AUTOSAR XML (schema 4-3-0)
package /Impl_SWC_FDC_ARPkg
  swc implementation Impl_SWC_FDC_type: programming-language=C, sw-version=1.0.0, vendor-id=0, behavior=SWC_FDC_type_IB
    code-descriptors:
      code SRC: artifact-descriptors=autosar-engineering-object={short-label=EngObject, category=SWSRC}
    resource consumption ResourceConsumption
      memory section MEM_SWC_FDC_CAL: size=0, sw-addrmethod=CAL, symbol=CAL
      memory section MEM_SWC_FDC_CODE: size=0, sw-addrmethod=CODE, symbol=CODE
package /SWC_FDC_ARPkg
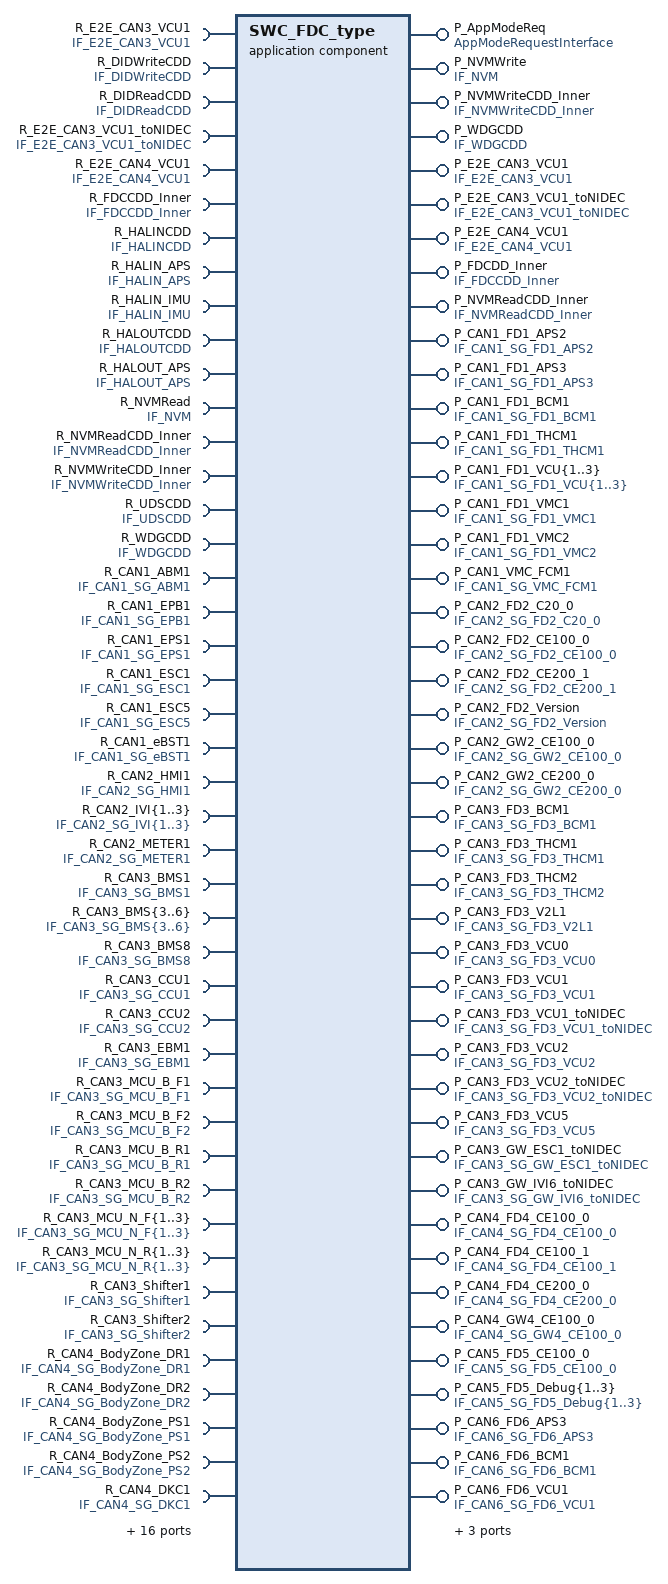
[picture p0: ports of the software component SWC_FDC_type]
  application sw component type SWC_FDC_type
    51 x provide port:
      P_AppModeReq: provided-interface=AppModeRequestInterface
      P_NVMWrite: nv-provide-com-spec{ram-block-init-value=ValueSpecification_:256 x 0, rom-block-init-value=ValueSpecification_:256 x 0, variable=NV_FVTDataArray}, provided-interface=IF_NVM
      P_NVMWriteCDD_Inner: provided-interface=IF_NVMWriteCDD_Inner
      P_WDGCDD: provided-interface=IF_WDGCDD
      P_E2E_CAN3_VCU1: provided-interface=IF_E2E_CAN3_VCU1
      P_E2E_CAN3_VCU1_toNIDEC: provided-interface=IF_E2E_CAN3_VCU1_toNIDEC
      P_E2E_CAN4_VCU1: provided-interface=IF_E2E_CAN4_VCU1
      P_FDCDD_Inner: provided-interface=IF_FDCCDD_Inner
      P_NVMReadCDD_Inner: provided-interface=IF_NVMReadCDD_Inner
      P_CAN1_FD1_APS2: provided-interface=IF_CAN1_SG_FD1_APS2
      P_CAN1_FD1_APS3: provided-interface=IF_CAN1_SG_FD1_APS3
      P_CAN1_FD1_BCM1: provided-interface=IF_CAN1_SG_FD1_BCM1
      P_CAN1_FD1_THCM1: provided-interface=IF_CAN1_SG_FD1_THCM1
      P_CAN1_FD1_VCU{1..3}: provided-interface=IF_CAN1_SG_FD1_VCU{1..3}
      P_CAN1_FD1_VMC1: provided-interface=IF_CAN1_SG_FD1_VMC1
      P_CAN1_FD1_VMC2: provided-interface=IF_CAN1_SG_FD1_VMC2
      P_CAN1_VMC_FCM1: provided-interface=IF_CAN1_SG_VMC_FCM1
      P_CAN2_FD2_C20_0: provided-interface=IF_CAN2_SG_FD2_C20_0
      P_CAN2_FD2_CE100_0: provided-interface=IF_CAN2_SG_FD2_CE100_0
      P_CAN2_FD2_CE200_1: provided-interface=IF_CAN2_SG_FD2_CE200_1
      P_CAN2_FD2_Version: provided-interface=IF_CAN2_SG_FD2_Version
      P_CAN2_GW2_CE100_0: provided-interface=IF_CAN2_SG_GW2_CE100_0
      P_CAN2_GW2_CE200_0: provided-interface=IF_CAN2_SG_GW2_CE200_0
      P_CAN3_FD3_BCM1: provided-interface=IF_CAN3_SG_FD3_BCM1
      P_CAN3_FD3_THCM1: provided-interface=IF_CAN3_SG_FD3_THCM1
      P_CAN3_FD3_THCM2: provided-interface=IF_CAN3_SG_FD3_THCM2
      P_CAN3_FD3_V2L1: provided-interface=IF_CAN3_SG_FD3_V2L1
      P_CAN3_FD3_VCU0: provided-interface=IF_CAN3_SG_FD3_VCU0
      P_CAN3_FD3_VCU1: provided-interface=IF_CAN3_SG_FD3_VCU1
      P_CAN3_FD3_VCU1_toNIDEC: provided-interface=IF_CAN3_SG_FD3_VCU1_toNIDEC
      P_CAN3_FD3_VCU2: provided-interface=IF_CAN3_SG_FD3_VCU2
      P_CAN3_FD3_VCU2_toNIDEC: provided-interface=IF_CAN3_SG_FD3_VCU2_toNIDEC
      P_CAN3_FD3_VCU5: provided-interface=IF_CAN3_SG_FD3_VCU5
      P_CAN3_GW_ESC1_toNIDEC: provided-interface=IF_CAN3_SG_GW_ESC1_toNIDEC
      P_CAN3_GW_IVI6_toNIDEC: provided-interface=IF_CAN3_SG_GW_IVI6_toNIDEC
      P_CAN4_FD4_CE100_0: provided-interface=IF_CAN4_SG_FD4_CE100_0
      P_CAN4_FD4_CE100_1: provided-interface=IF_CAN4_SG_FD4_CE100_1
      P_CAN4_FD4_CE200_0: provided-interface=IF_CAN4_SG_FD4_CE200_0
      P_CAN4_GW4_CE100_0: provided-interface=IF_CAN4_SG_GW4_CE100_0
      P_CAN5_FD5_CE100_0: provided-interface=IF_CAN5_SG_FD5_CE100_0
      P_CAN5_FD5_Debug{1..3}: provided-interface=IF_CAN5_SG_FD5_Debug{1..3}
      P_CAN6_FD6_APS3: provided-interface=IF_CAN6_SG_FD6_APS3
      P_CAN6_FD6_BCM1: provided-interface=IF_CAN6_SG_FD6_BCM1
      P_CAN6_FD6_VCU1: provided-interface=IF_CAN6_SG_FD6_VCU1
      P_CAN6_FD6_VCU2: provided-interface=IF_CAN6_SG_FD6_VCU2
      P_CAN6_FD6_VMC1: provided-interface=IF_CAN6_SG_FD6_VMC1
      P_CAN6_GW6_CE100_0: provided-interface=IF_CAN6_SG_GW6_CE100_0
    74 x require port:
      R_E2E_CAN3_VCU1: required-interface=IF_E2E_CAN3_VCU1
      R_DIDWriteCDD: required-interface=IF_DIDWriteCDD
      R_DIDReadCDD: required-interface=IF_DIDReadCDD
      R_E2E_CAN3_VCU1_toNIDEC: required-interface=IF_E2E_CAN3_VCU1_toNIDEC
      R_E2E_CAN4_VCU1: required-interface=IF_E2E_CAN4_VCU1
      R_FDCCDD_Inner: required-interface=IF_FDCCDD_Inner
      R_HALINCDD: required-interface=IF_HALINCDD
      R_HALIN_APS: required-interface=IF_HALIN_APS
      R_HALIN_IMU: required-interface=IF_HALIN_IMU
      R_HALOUTCDD: required-interface=IF_HALOUTCDD
      R_HALOUT_APS: required-interface=IF_HALOUT_APS
      R_NVMRead: nv-require-com-spec{init-value=256 x 0, variable=NV_FVTDataArray}, required-interface=IF_NVM
      R_NVMReadCDD_Inner: required-interface=IF_NVMReadCDD_Inner
      R_NVMWriteCDD_Inner: required-interface=IF_NVMWriteCDD_Inner
      R_UDSCDD: required-interface=IF_UDSCDD
      R_WDGCDD: required-interface=IF_WDGCDD
      R_CAN1_ABM1: required-interface=IF_CAN1_SG_ABM1
      R_CAN1_EPB1: required-interface=IF_CAN1_SG_EPB1
      R_CAN1_EPS1: required-interface=IF_CAN1_SG_EPS1
      R_CAN1_ESC1: required-interface=IF_CAN1_SG_ESC1
      R_CAN1_ESC5: required-interface=IF_CAN1_SG_ESC5
      R_CAN1_eBST1: required-interface=IF_CAN1_SG_eBST1
      R_CAN2_HMI1: required-interface=IF_CAN2_SG_HMI1
      R_CAN2_IVI{1..3}: required-interface=IF_CAN2_SG_IVI{1..3}
      R_CAN2_METER1: required-interface=IF_CAN2_SG_METER1
      R_CAN3_BMS1: required-interface=IF_CAN3_SG_BMS1
      R_CAN3_BMS{3..6}: required-interface=IF_CAN3_SG_BMS{3..6}
      R_CAN3_BMS8: required-interface=IF_CAN3_SG_BMS8
      R_CAN3_CCU1: required-interface=IF_CAN3_SG_CCU1
      R_CAN3_CCU2: required-interface=IF_CAN3_SG_CCU2
      R_CAN3_EBM1: required-interface=IF_CAN3_SG_EBM1
      R_CAN3_MCU_B_F1: required-interface=IF_CAN3_SG_MCU_B_F1
      R_CAN3_MCU_B_F2: required-interface=IF_CAN3_SG_MCU_B_F2
      R_CAN3_MCU_B_R1: required-interface=IF_CAN3_SG_MCU_B_R1
      R_CAN3_MCU_B_R2: required-interface=IF_CAN3_SG_MCU_B_R2
      R_CAN3_MCU_N_F{1..3}: required-interface=IF_CAN3_SG_MCU_N_F{1..3}
      R_CAN3_MCU_N_R{1..3}: required-interface=IF_CAN3_SG_MCU_N_R{1..3}
      R_CAN3_Shifter1: required-interface=IF_CAN3_SG_Shifter1
      R_CAN3_Shifter2: required-interface=IF_CAN3_SG_Shifter2
      R_CAN4_BodyZone_DR1: required-interface=IF_CAN4_SG_BodyZone_DR1
      R_CAN4_BodyZone_DR2: required-interface=IF_CAN4_SG_BodyZone_DR2
      R_CAN4_BodyZone_PS1: required-interface=IF_CAN4_SG_BodyZone_PS1
      R_CAN4_BodyZone_PS2: required-interface=IF_CAN4_SG_BodyZone_PS2
      R_CAN4_DKC1: required-interface=IF_CAN4_SG_DKC1
      R_CAN4_DKC2: required-interface=IF_CAN4_SG_DKC2
      R_CAN4_PTG1: required-interface=IF_CAN4_SG_PTG1
      R_CAN4_ZONE_DR1: required-interface=IF_CAN4_SG_ZONE_DR1
      R_CAN4_ZONE_DR_VCU: required-interface=IF_CAN4_SG_ZONE_DR_VCU
      R_CAN4_ZONE_FR1: required-interface=IF_CAN4_SG_ZONE_FR1
      R_CAN4_ZONE_FR_VCU: required-interface=IF_CAN4_SG_ZONE_FR_VCU
      R_CAN4_zGW_APTC1: required-interface=IF_CAN4_SG_zGW_APTC1
      R_CAN4_zGW_CANFr1: required-interface=IF_CAN4_SG_zGW_CANFr1
      R_CAN4_zGW_LINDr1: required-interface=IF_CAN4_SG_zGW_LINDr1
      R_CAN4_zGW_LINDr2: required-interface=IF_CAN4_SG_zGW_LINDr2
      R_CAN4_zGW_LINFr1: required-interface=IF_CAN4_SG_zGW_LINFr1
      R_CAN4_zGW_LINFr2: required-interface=IF_CAN4_SG_zGW_LINFr2
      R_CAN4_zGW_SEAT1: required-interface=IF_CAN4_SG_zGW_SEAT1
      R_CAN5_TBOX{1..3}: required-interface=IF_CAN5_SG_TBOX{1..3}
      R_CAN6_FCM{1..4}: required-interface=IF_CAN6_SG_FCM{1..4}
      R_CAN6_SRR1: required-interface=IF_CAN6_SG_SRR1
    behavior SWC_FDC_type_IB: data-type-mapping=AppModeTypeMap, handle-termination-and-restart=NO-SUPPORT
      10 x timing event:
        TE_100ms: start-on-event=run_SWC_FDC_Tx_100ms, period=0.1
        TE_1000ms: start-on-event=run_SWC_FDC_Tx_1000ms, period=1
        TE_20ms: start-on-event=run_SWC_FDC_Tx_20ms, period=0.02
        TE_500ms: start-on-event=run_SWC_FDC_Tx_500ms, period=0.5
        TE_5000ms: start-on-event=run_SWC_FDC_Tx_5000ms, period=5
        TE_10ms: start-on-event=run_SWC_FDC_Tx_10ms, period=0.01
        TE_5ms: start-on-event=run_SWC_FDC_RxTx_5ms, period=0.005
        TE_CDD_10ms: start-on-event=run_SWC_FDC_CDD_10ms, period=0.01
        TE_PAS_1ms: start-on-event=run_SWC_FDC_PAS_1ms, period=0.001
        TE_UDS_10ms: start-on-event=run_SWC_FDC_UDS_10ms, period=0.01
      9 x operation invoked event:
        oie_P_E2E_CAN3_VCU1_CSOP_Write_CAN3_VCU1: start-on-event=run_SWC_FDC_E2E_Write_CAN3VCU1, operation=P_E2E_CAN3_VCU1.CSOP_Write_CAN3_VCU1
        oie_P_E2E_CAN3_VCU1_CSOP_Write_CAN3_VCU1_toNIDEC: start-on-event=run_SWC_FDC_E2E_Write_CAN3VCU1_toNIDEC, operation=P_E2E_CAN3_VCU1_toNIDEC.CSOP_Write_CAN3_VCU1_toNIDEC
        oie_P_E2E_CAN4_VCU1_CSOP_Write_CAN4_VCU1: start-on-event=run_SWC_FDC_E2E_Write_CAN4VCU1, operation=P_E2E_CAN4_VCU1.CSOP_Write_CAN4_VCU1
        oie_P_FDCDD_Inner_CSOP_FDC_AppCallSleep: start-on-event=run_SWC_FDC_AppCallSleep, operation=P_FDCDD_Inner.CSOP_FDC_AppCallSleep
        oie_P_NVMReadCDD_Inner_NVM_ReadOperation: start-on-event=run_SWC_FDC_NvmRead, operation=P_NVMReadCDD_Inner.NVM_ReadOperation
        oie_P_NVMWriteCDD_Inner_NVM_WriteOperation: start-on-event=run_SWC_FDC_NvmWrite, operation=P_NVMWriteCDD_Inner.NVM_WriteOperation
        oie_P_WDGCDD_CSOP_Call_WDG_AppEnd: start-on-event=run_SWC_FDC_AppCallWDG_End, operation=P_WDGCDD.CSOP_Call_WDG_AppEnd
        oie_P_WDGCDD_CSOP_Call_WDG_AppStart: start-on-event=run_SWC_FDC_AppCallWDG_StartUp, operation=P_WDGCDD.CSOP_Call_WDG_AppStart
        oie_P_WDGCDD_CSOP_Call_Watchdog: start-on-event=run_SWC_FDC_AppCallWDG, operation=P_WDGCDD.CSOP_Call_Watchdog
      explicit-inter-runnable-variables:
        51 x data:
          IRV_ms10_CAN1_SG_FD1_APS3: type=DT_CAN1_SG_FD1_APS3
          IRV_ms10_CAN1_SG_FD1_VCU2: type=DT_CAN1_SG_FD1_VCU2
          IRV_ms10_CAN1_SG_FD1_VCU3: type=DT_CAN1_SG_FD1_VCU3
          IRV_ms10_CAN1_SG_VMC_FCM1: type=DT_CAN1_SG_VMC_FCM1
          IRV_ms10_CAN3_SG_FD3_VCU0: type=DT_CAN3_SG_FD3_VCU0
          IRV_ms10_CAN3_SG_FD3_VCU2: type=DT_CAN3_SG_FD3_VCU2
          IRV_ms10_CAN3_SG_FD3_VCU2_toNIDEC: type=DT_CAN3_SG_FD3_VCU2_toNIDEC
          IRV_ms10_CAN3_SG_FD3_VCU5: type=DT_CAN3_SG_FD3_VCU5
          IRV_ms10_CAN3_SG_GW_ESC1_toNIDEC: type=DT_CAN3_SG_GW_ESC1_toNIDEC
          IRV_ms10_CAN5_SG_FD5_Debug3: type=DT_CAN5_SG_FD5_Debug3
          IRV_ms10_CAN6_SG_FD6_APS3: type=DT_CAN6_SG_FD6_APS3
          IRV_ms10_CAN6_SG_FD6_VCU2: type=DT_CAN6_SG_FD6_VCU2
          IRV_ms100_CAN1_SG_FD1_THCM1: type=DT_CAN1_SG_FD1_THCM1
          IRV_ms100_CAN3_SG_FD3_THCM1: type=DT_CAN3_SG_FD3_THCM1
          IRV_ms1000_CAN3_SG_GW_IVI6_toNIDEC: type=DT_CAN3_SG_GW_IVI6_toNIDEC
          IRV_ms20_CAN1_SG_FD1_APS2: type=DT_CAN1_SG_FD1_APS2
          IRV_ms20_CAN2_SG_FD2_C20_0: type=DT_CAN2_SG_FD2_C20_0
          IRV_ms500_CAN1_SG_FD1_VMC2: type=DT_CAN1_SG_FD1_VMC2
          IRV_ms5000_CAN2_SG_FD2_Version: type=DT_CAN2_SG_FD2_Version
          IRV_E2E_CAN3_SG_FD3_VCU1: type=DT_CAN3_SG_FD3_VCU1
          IRV_E2E_CAN3_SG_FD3_VCU1_toNIDEC: type=DT_CAN3_SG_FD3_VCU1_toNIDEC
          IRV_E2E_CAN4_SG_FD4_CE100_0: type=DT_CAN4_SG_FD4_CE100_0
          IRV_f32_ApsOutVehSpdSig: type=float32
          IRV_u16Array4_ApsInDist: type=u16_APSArray4_type
          IRV_u8Array12_ApsInUssSta: type=u8_USSArray12_type
          IRV_u8Array256_NvmReadArray: type=u8_FVTNVMArray256_type
          IRV_u8Array256_NvmWriteArray: type=u8_FVTNVMArray256_type
          IRV_u8Array8_ApsInLevel: type=u8_APSLevelArray8_type
          IRV_u8Array8_PasInDist: type=u8_PASArray8_type
          IRV_u8Array9_TPMSData: type=u8_TPMSDataArray9_type
          IRV_u8_ApsInPASChime: type=uint8
          IRV_u8_ApsInSensorLayout: type=uint8
          IRV_u8_ApsInSysFailSta: type=uint8
          IRV_u8_ApsInSysMode: type=uint8
          IRV_u8_ApsOutGearPosnSig: type=uint8
          IRV_u8_ApsOutSendChrgPlugSta: type=uint8
          IRV_u8_ApsOutSetFrSensorOnCmd: type=uint8
          IRV_u8_ApsOutSetFrSensorSwTOCmd: type=uint8
          IRV_u8_ApsOutSetVehSpdTOCmd: type=uint8
          IRV_u8_CTDSW: type=uint8
          IRV_u8_CrashSignal: type=uint8
          IRV_u8_DrDoorSW: type=uint8
          IRV_u8_HazardSW: type=uint8
          IRV_u8_HoodSW: type=uint8
          IRV_u8_PsDoorSW: type=uint8
          IRV_u8_RLDoorSW: type=uint8
          IRV_u8_RRDoorSW: type=uint8
          IRV_u8_SeatSW: type=uint8
          IRV_u8_TPMSDataInSta: type=boolean
          IRV_u8_TailgateSW: type=uint8
          IRV_u8_TrunkHanSW: type=uint8
      port-api-options:
        enable-take-address=false, indirect-api=false, port=P_FDCDD_Inner
        enable-take-address=false, indirect-api=false, port=P_NVMReadCDD_Inner
        enable-take-address=false, indirect-api=false, port=P_NVMWriteCDD_Inner
        enable-take-address=false, indirect-api=false, port=P_E2E_CAN3_VCU1
        enable-take-address=false, indirect-api=false, port=P_E2E_CAN3_VCU1_toNIDEC
        enable-take-address=false, indirect-api=false, port=P_E2E_CAN4_VCU1
        enable-take-address=false, indirect-api=false, port=P_WDGCDD
      19 x runnable:
        run_SWC_FDC_Tx_100ms
          data-send-points:
            access dsp_CAN1_SG_FD1_THCM1: accessed-variable=P_CAN1_FD1_THCM1.CAN1_SG_FD1_THCM1
            access dsp_CAN3_SG_FD3_THCM1: accessed-variable=P_CAN3_FD3_THCM1.CAN3_SG_FD3_THCM1
          read-local-variables:
            access IRV_ms100_CAN1_SG_FD1_THCM1: accessed-variable=IRV_ms100_CAN1_SG_FD1_THCM1
            access IRV_ms100_CAN3_SG_FD3_THCM1: accessed-variable=IRV_ms100_CAN3_SG_FD3_THCM1
        run_SWC_FDC_Tx_1000ms
          data-send-points:
            access dsp_CAN3_SG_GW_IVI6_toNIDEC: accessed-variable=P_CAN3_GW_IVI6_toNIDEC.CAN3_SG_GW_IVI6_toNIDEC
          read-local-variables:
            access IRV_ms1000_CAN3_SG_GW_IVI6_toNIDEC: accessed-variable=IRV_ms1000_CAN3_SG_GW_IVI6_toNIDEC
        run_SWC_FDC_Tx_20ms
          data-send-points:
            access dsp_CAN1_SG_FD1_APS2: accessed-variable=P_CAN1_FD1_APS2.CAN1_SG_FD1_APS2
            access dsp_CAN2_SG_FD2_C20_0: accessed-variable=P_CAN2_FD2_C20_0.CAN2_SG_FD2_C20_0
          read-local-variables:
            access IRV_ms20_CAN1_SG_FD1_APS2: accessed-variable=IRV_ms20_CAN1_SG_FD1_APS2
            access IRV_ms20_CAN2_SG_FD2_C20_0: accessed-variable=IRV_ms20_CAN2_SG_FD2_C20_0
        run_SWC_FDC_Tx_500ms
          data-send-points:
            access dsp_CAN1_SG_FD1_VMC2: accessed-variable=P_CAN1_FD1_VMC2.CAN1_SG_FD1_VMC2
          read-local-variables:
            access IRV_ms500_CAN1_SG_FD1_VMC2: accessed-variable=IRV_ms500_CAN1_SG_FD1_VMC2
        run_SWC_FDC_Tx_5000ms
          data-send-points:
            access dsp_CAN2_SG_FD2_Version: accessed-variable=P_CAN2_FD2_Version.CAN2_SG_FD2_Version
          read-local-variables:
            access IRV_ms5000_CAN2_SG_FD2_Version: accessed-variable=IRV_ms5000_CAN2_SG_FD2_Version
        run_SWC_FDC_AppCallSleep
          data-send-points:
            access dsp_requestedMode: accessed-variable=P_AppModeReq.requestedMode
        run_SWC_FDC_AppCallWDG
        run_SWC_FDC_AppCallWDG_End
        run_SWC_FDC_AppCallWDG_StartUp
        run_SWC_FDC_CDD_10ms
          sync call scp_CSOP_HALINCDD_IOEXPANDER: operation=R_HALINCDD.CSOP_HALINCDD_IOEXPANDER, timeout=0.0
          written-local-variables:
            11 x access:
              IRV_u8_CTDSW: accessed-variable=IRV_u8_CTDSW
              IRV_u8_CrashSignal: accessed-variable=IRV_u8_CrashSignal
              IRV_u8_DrDoorSW: accessed-variable=IRV_u8_DrDoorSW
              IRV_u8_HazardSW: accessed-variable=IRV_u8_HazardSW
              IRV_u8_HoodSW: accessed-variable=IRV_u8_HoodSW
              IRV_u8_PsDoorSW: accessed-variable=IRV_u8_PsDoorSW
              IRV_u8_RLDoorSW: accessed-variable=IRV_u8_RLDoorSW
              IRV_u8_RRDoorSW: accessed-variable=IRV_u8_RRDoorSW
              IRV_u8_SeatSW: accessed-variable=IRV_u8_SeatSW
              IRV_u8_TailgateSW: accessed-variable=IRV_u8_TailgateSW
              IRV_u8_TrunkHanSW: accessed-variable=IRV_u8_TrunkHanSW
        run_SWC_FDC_E2E_Write_CAN3VCU1
          data-send-points:
            access dsp_CAN3_SG_FD3_VCU1: accessed-variable=P_CAN3_FD3_VCU1.CAN3_SG_FD3_VCU1
          read-local-variables:
            access IRV_E2E_CAN3_SG_FD3_VCU1: accessed-variable=IRV_E2E_CAN3_SG_FD3_VCU1
        run_SWC_FDC_E2E_Write_CAN3VCU1_toNIDEC
          data-send-points:
            access dsp_CAN3_SG_FD3_VCU1_toNIDEC: accessed-variable=P_CAN3_FD3_VCU1_toNIDEC.CAN3_SG_FD3_VCU1_toNIDEC
          read-local-variables:
            access IRV_E2E_CAN3_SG_FD3_VCU1_toNIDEC: accessed-variable=IRV_E2E_CAN3_SG_FD3_VCU1_toNIDEC
        run_SWC_FDC_E2E_Write_CAN4VCU1
          data-send-points:
            access dsp_CAN4_SG_FD4_CE100_0: accessed-variable=P_CAN4_FD4_CE100_0.CAN4_SG_FD4_CE100_0
          read-local-variables:
            access IRV_E2E_CAN4_SG_FD4_CE100_0: accessed-variable=IRV_E2E_CAN4_SG_FD4_CE100_0
        run_SWC_FDC_NvmRead
          data-receive-point-by-arguments:
            access drparg_NV_FVTDataArray: accessed-variable=R_NVMRead.NV_FVTDataArray
          written-local-variables:
            access IRV_u8Array256_NvmReadArray: accessed-variable=IRV_u8Array256_NvmReadArray
        run_SWC_FDC_NvmWrite
          data-send-points:
            access dsp_NV_FVTDataArray: accessed-variable=P_NVMWrite.NV_FVTDataArray
          read-local-variables:
            access IRV_u8Array256_NvmWriteArray: accessed-variable=IRV_u8Array256_NvmWriteArray
        run_SWC_FDC_PAS_1ms
          sync call scp_CSOP_PAS_Handler: operation=R_HALINCDD.CSOP_PAS_Handler, timeout=0.0
        run_SWC_FDC_RxTx_5ms
          data-receive-point-by-arguments:
            58 x access:
              drparg_CAN1_SG_ABM1: accessed-variable=R_CAN1_ABM1.CAN1_SG_ABM1
              drparg_CAN1_SG_EPB1: accessed-variable=R_CAN1_EPB1.CAN1_SG_EPB1
              drparg_CAN1_SG_EPS1: accessed-variable=R_CAN1_EPS1.CAN1_SG_EPS1
              drparg_CAN1_SG_ESC1: accessed-variable=R_CAN1_ESC1.CAN1_SG_ESC1
              drparg_CAN1_SG_ESC5: accessed-variable=R_CAN1_ESC5.CAN1_SG_ESC5
              drparg_CAN1_SG_eBST1: accessed-variable=R_CAN1_eBST1.CAN1_SG_eBST1
              drparg_CAN2_SG_HMI1: accessed-variable=R_CAN2_HMI1.CAN2_SG_HMI1
              drparg_CAN2_SG_IVI{1..3}: accessed-variable=R_CAN2_IVI{1..3}.CAN2_SG_IVI{1..3}
              drparg_CAN2_SG_METER1: accessed-variable=R_CAN2_METER1.CAN2_SG_METER1
              drparg_CAN3_SG_BMS1: accessed-variable=R_CAN3_BMS1.CAN3_SG_BMS1
              drparg_CAN3_SG_BMS{3..6}: accessed-variable=R_CAN3_BMS{3..6}.CAN3_SG_BMS{3..6}
              drparg_CAN3_SG_BMS8: accessed-variable=R_CAN3_BMS8.CAN3_SG_BMS8
              drparg_CAN3_SG_CCU1: accessed-variable=R_CAN3_CCU1.CAN3_SG_CCU1
              drparg_CAN3_SG_CCU2: accessed-variable=R_CAN3_CCU2.CAN3_SG_CCU2
              drparg_CAN3_SG_EBM1: accessed-variable=R_CAN3_EBM1.CAN3_SG_EBM1
              drparg_CAN3_SG_MCU_B_F1: accessed-variable=R_CAN3_MCU_B_F1.CAN3_SG_MCU_B_F1
              drparg_CAN3_SG_MCU_B_F2: accessed-variable=R_CAN3_MCU_B_F2.CAN3_SG_MCU_B_F2
              drparg_CAN3_SG_MCU_B_R1: accessed-variable=R_CAN3_MCU_B_R1.CAN3_SG_MCU_B_R1
              drparg_CAN3_SG_MCU_B_R2: accessed-variable=R_CAN3_MCU_B_R2.CAN3_SG_MCU_B_R2
              drparg_CAN3_SG_MCU_N_F{1..3}: accessed-variable=R_CAN3_MCU_N_F{1..3}.CAN3_SG_MCU_N_F{1..3}
              drparg_CAN3_SG_MCU_N_R{1..3}: accessed-variable=R_CAN3_MCU_N_R{1..3}.CAN3_SG_MCU_N_R{1..3}
              drparg_CAN3_SG_Shifter1: accessed-variable=R_CAN3_Shifter1.CAN3_SG_Shifter1
              drparg_CAN3_SG_Shifter2: accessed-variable=R_CAN3_Shifter2.CAN3_SG_Shifter2
              drparg_CAN4_SG_BodyZone_DR1: accessed-variable=R_CAN4_BodyZone_DR1.CAN4_SG_BodyZone_DR1
              drparg_CAN4_SG_BodyZone_DR2: accessed-variable=R_CAN4_BodyZone_DR2.CAN4_SG_BodyZone_DR2
              drparg_CAN4_SG_BodyZone_PS1: accessed-variable=R_CAN4_BodyZone_PS1.CAN4_SG_BodyZone_PS1
              drparg_CAN4_SG_BodyZone_PS2: accessed-variable=R_CAN4_BodyZone_PS2.CAN4_SG_BodyZone_PS2
              drparg_CAN4_SG_DKC1: accessed-variable=R_CAN4_DKC1.CAN4_SG_DKC1
              drparg_CAN4_SG_DKC2: accessed-variable=R_CAN4_DKC2.CAN4_SG_DKC2
              drparg_CAN4_SG_PTG1: accessed-variable=R_CAN4_PTG1.CAN4_SG_PTG1
              drparg_CAN4_SG_ZONE_DR1: accessed-variable=R_CAN4_ZONE_DR1.CAN4_SG_ZONE_DR1
              drparg_CAN4_SG_ZONE_DR_VCU: accessed-variable=R_CAN4_ZONE_DR_VCU.CAN4_SG_ZONE_DR_VCU
              drparg_CAN4_SG_ZONE_FR1: accessed-variable=R_CAN4_ZONE_FR1.CAN4_SG_ZONE_FR1
              drparg_CAN4_SG_ZONE_FR_VCU: accessed-variable=R_CAN4_ZONE_FR_VCU.CAN4_SG_ZONE_FR_VCU
              drparg_CAN4_SG_zGW_APTC1: accessed-variable=R_CAN4_zGW_APTC1.CAN4_SG_zGW_APTC1
              drparg_CAN4_SG_zGW_CANFr1: accessed-variable=R_CAN4_zGW_CANFr1.CAN4_SG_zGW_CANFr1
              drparg_CAN4_SG_zGW_LINDr1: accessed-variable=R_CAN4_zGW_LINDr1.CAN4_SG_zGW_LINDr1
              drparg_CAN4_SG_zGW_LINDr2: accessed-variable=R_CAN4_zGW_LINDr2.CAN4_SG_zGW_LINDr2
              drparg_CAN4_SG_zGW_LINFr1: accessed-variable=R_CAN4_zGW_LINFr1.CAN4_SG_zGW_LINFr1
              drparg_CAN4_SG_zGW_LINFr2: accessed-variable=R_CAN4_zGW_LINFr2.CAN4_SG_zGW_LINFr2
              drparg_CAN4_SG_zGW_SEAT1: accessed-variable=R_CAN4_zGW_SEAT1.CAN4_SG_zGW_SEAT1
              drparg_CAN5_SG_TBOX{1..3}: accessed-variable=R_CAN5_TBOX{1..3}.CAN5_SG_TBOX{1..3}
              drparg_CAN6_SG_FCM{1..4}: accessed-variable=R_CAN6_FCM{1..4}.CAN6_SG_FCM{1..4}
              drparg_CAN6_SG_SRR1: accessed-variable=R_CAN6_SRR1.CAN6_SG_SRR1
          data-send-points:
            20 x access:
              dsp_CAN1_SG_FD1_BCM1: accessed-variable=P_CAN1_FD1_BCM1.CAN1_SG_FD1_BCM1
              dsp_CAN1_SG_FD1_VCU1: accessed-variable=P_CAN1_FD1_VCU1.CAN1_SG_FD1_VCU1
              dsp_CAN1_SG_FD1_VMC1: accessed-variable=P_CAN1_FD1_VMC1.CAN1_SG_FD1_VMC1
              dsp_CAN2_SG_FD2_CE100_0: accessed-variable=P_CAN2_FD2_CE100_0.CAN2_SG_FD2_CE100_0
              dsp_CAN2_SG_FD2_CE200_1: accessed-variable=P_CAN2_FD2_CE200_1.CAN2_SG_FD2_CE200_1
              dsp_CAN2_SG_GW2_CE100_0: accessed-variable=P_CAN2_GW2_CE100_0.CAN2_SG_GW2_CE100_0
              dsp_CAN2_SG_GW2_CE200_0: accessed-variable=P_CAN2_GW2_CE200_0.CAN2_SG_GW2_CE200_0
              dsp_CAN3_SG_FD3_BCM1: accessed-variable=P_CAN3_FD3_BCM1.CAN3_SG_FD3_BCM1
              dsp_CAN3_SG_FD3_THCM2: accessed-variable=P_CAN3_FD3_THCM2.CAN3_SG_FD3_THCM2
              dsp_CAN3_SG_FD3_V2L1: accessed-variable=P_CAN3_FD3_V2L1.CAN3_SG_FD3_V2L1
              dsp_CAN4_SG_FD4_CE100_1: accessed-variable=P_CAN4_FD4_CE100_1.CAN4_SG_FD4_CE100_1
              dsp_CAN4_SG_FD4_CE200_0: accessed-variable=P_CAN4_FD4_CE200_0.CAN4_SG_FD4_CE200_0
              dsp_CAN4_SG_GW4_CE100_0: accessed-variable=P_CAN4_GW4_CE100_0.CAN4_SG_GW4_CE100_0
              dsp_CAN5_SG_FD5_CE100_0: accessed-variable=P_CAN5_FD5_CE100_0.CAN5_SG_FD5_CE100_0
              dsp_CAN5_SG_FD5_Debug1: accessed-variable=P_CAN5_FD5_Debug1.CAN5_SG_FD5_Debug1
              dsp_CAN5_SG_FD5_Debug2: accessed-variable=P_CAN5_FD5_Debug2.CAN5_SG_FD5_Debug2
              dsp_CAN6_SG_FD6_BCM1: accessed-variable=P_CAN6_FD6_BCM1.CAN6_SG_FD6_BCM1
              dsp_CAN6_SG_FD6_VCU1: accessed-variable=P_CAN6_FD6_VCU1.CAN6_SG_FD6_VCU1
              dsp_CAN6_SG_FD6_VMC1: accessed-variable=P_CAN6_FD6_VMC1.CAN6_SG_FD6_VMC1
              dsp_CAN6_SG_GW6_CE100_0: accessed-variable=P_CAN6_GW6_CE100_0.CAN6_SG_GW6_CE100_0
          read-local-variables:
            22 x access:
              IRV_u16Array4_ApsInDist: accessed-variable=IRV_u16Array4_ApsInDist
              IRV_u8Array12_ApsInUssSta: accessed-variable=IRV_u8Array12_ApsInUssSta
              IRV_u8Array256_NvmReadArray: accessed-variable=IRV_u8Array256_NvmReadArray
              IRV_u8Array8_ApsInLevel: accessed-variable=IRV_u8Array8_ApsInLevel
              IRV_u8Array8_PasInDist: accessed-variable=IRV_u8Array8_PasInDist
              IRV_u8Array9_TPMSData: accessed-variable=IRV_u8Array9_TPMSData
              IRV_u8_ApsInPASChime: accessed-variable=IRV_u8_ApsInPASChime
              IRV_u8_ApsInSensorLayout: accessed-variable=IRV_u8_ApsInSensorLayout
              IRV_u8_ApsInSysFailSta: accessed-variable=IRV_u8_ApsInSysFailSta
              IRV_u8_ApsInSysMode: accessed-variable=IRV_u8_ApsInSysMode
              IRV_u8_CTDSW: accessed-variable=IRV_u8_CTDSW
              IRV_u8_CrashSignal: accessed-variable=IRV_u8_CrashSignal
              IRV_u8_DrDoorSW: accessed-variable=IRV_u8_DrDoorSW
              IRV_u8_HazardSW: accessed-variable=IRV_u8_HazardSW
              IRV_u8_HoodSW: accessed-variable=IRV_u8_HoodSW
              IRV_u8_PsDoorSW: accessed-variable=IRV_u8_PsDoorSW
              IRV_u8_RLDoorSW: accessed-variable=IRV_u8_RLDoorSW
              IRV_u8_RRDoorSW: accessed-variable=IRV_u8_RRDoorSW
              IRV_u8_SeatSW: accessed-variable=IRV_u8_SeatSW
              IRV_u8_TPMSDataInSta: accessed-variable=IRV_u8_TPMSDataInSta
              IRV_u8_TailgateSW: accessed-variable=IRV_u8_TailgateSW
              IRV_u8_TrunkHanSW: accessed-variable=IRV_u8_TrunkHanSW
          112 x sync call, all with timeout=0.0:
            scp_CSOP_nmGetCan6TxErrorCount: operation=R_HALINCDD.CSOP_nmGetCan6TxErrorCount
            scp_CSOP_nmGetCan6RxErrorCount: operation=R_HALINCDD.CSOP_nmGetCan6RxErrorCount
            scp_CSOP_nmGetCan5TxErrorCount: operation=R_HALINCDD.CSOP_nmGetCan5TxErrorCount
            scp_CSOP_nmGetCan5RxErrorCount: operation=R_HALINCDD.CSOP_nmGetCan5RxErrorCount
            scp_CSOP_nmGetCan4TxErrorCount: operation=R_HALINCDD.CSOP_nmGetCan4TxErrorCount
            scp_CSOP_nmGetCan4RxErrorCount: operation=R_HALINCDD.CSOP_nmGetCan4RxErrorCount
            scp_CSOP_nmGetCan3TxErrorCount: operation=R_HALINCDD.CSOP_nmGetCan3TxErrorCount
            scp_CSOP_nmGetCan3RxErrorCount: operation=R_HALINCDD.CSOP_nmGetCan3RxErrorCount
            scp_CSOP_nmGetCan2TxErrorCount: operation=R_HALINCDD.CSOP_nmGetCan2TxErrorCount
            scp_CSOP_nmGetCan2RxErrorCount: operation=R_HALINCDD.CSOP_nmGetCan2RxErrorCount
            scp_CSOP_nmGetCan1TxErrorCount: operation=R_HALINCDD.CSOP_nmGetCan1TxErrorCount
            scp_CSOP_nmGetCan1RxErrorCount: operation=R_HALINCDD.CSOP_nmGetCan1RxErrorCount
            scp_CSOP_AnyNmID: operation=R_HALINCDD.CSOP_AnyNmID
            scp_CSOP_AppNmStateReq: operation=R_HALOUTCDD.CSOP_AppNmStateReq
            scp_CSOP_ApsGetData: operation=R_HALIN_APS.CSOP_ApsGetData
            scp_CSOP_ApsSetData: operation=R_HALOUT_APS.CSOP_ApsSetData
            scp_CSOP_ApsSetTimeout: operation=R_HALOUT_APS.CSOP_ApsSetTimeout
            scp_CSOP_GetAcoreRebootCmd: operation=R_HALINCDD.CSOP_GetAcoreRebootCmd
            scp_CSOP_SetAcoreRebootCmdACK: operation=R_HALOUTCDD.CSOP_SetAcoreRebootCmdACK
            scp_CSOP_ReadPedalZeroPosReq: operation=R_HALINCDD.CSOP_ReadPedalZeroPosReq
            scp_CSOP_ResetPedalZeroPosReq: operation=R_HALINCDD.CSOP_ResetPedalZeroPosReq
            scp_CSOP_ResetPedalZeroPosDone: operation=R_HALINCDD.CSOP_ResetPedalZeroPosDone
            scp_CSOP_TPMSSensorIDRegGetSta: operation=R_HALINCDD.CSOP_TPMSSensorIDRegGetSta
            scp_CSOP_TPMSSensorIDRegSetResults: operation=R_HALINCDD.CSOP_TPMSSensorIDRegSetResults
            scp_CSOP_CAN{1..6}BusOff: operation=R_HALINCDD.CSOP_CAN{1..6}BusOff
            scp_CSOP_Call_WDG_AppEnd: operation=R_WDGCDD.CSOP_Call_WDG_AppEnd
            scp_CSOP_Call_WDG_AppStart: operation=R_WDGCDD.CSOP_Call_WDG_AppStart
            scp_CSOP_Call_Watchdog: operation=R_WDGCDD.CSOP_Call_Watchdog
            scp_CSOP_DIDgetDKCdata: operation=R_HALINCDD.CSOP_DIDgetDKCdata
            scp_CSOP_DIDgetXWDdata: operation=R_HALINCDD.CSOP_DIDgetXWDdata
            scp_CSOP_DKCDecrypt: operation=R_HALINCDD.CSOP_DKCDecrypt
            scp_CSOP_DdmClearDTCNotifica: operation=R_UDSCDD.CSOP_DdmClearDTCNotification
            scp_CSOP_DdmRestartOperation: operation=R_UDSCDD.CSOP_DdmRestartOperationCycle
            scp_CSOP_FDC_AppCallSleep: operation=R_FDCCDD_Inner.CSOP_FDC_AppCallSleep
            scp_CSOP_GetACoreReadyToSleep: operation=R_HALINCDD.CSOP_GetAcoreReadyToSleep
            scp_CSOP_GetAuxBattVoltage: operation=R_HALINCDD.CSOP_GetAuxBattVoltage
            scp_CSOP_GetBootReason: operation=R_HALINCDD.CSOP_GetBootReason
            scp_CSOP_GetBootPath: operation=R_HALINCDD.CSOP_GetBootPath
            scp_CSOP_GetEvccAplusPwrUpReq: operation=R_HALINCDD.CSOP_GetEvccAplusPwrUpReq
            scp_CSOP_GetHWID: operation=R_HALINCDD.u8Array4_HWID
            scp_CSOP_GetNmState: operation=R_HALINCDD.CSOP_GetNmState
            scp_CSOP_GetNvmProtectState: operation=R_HALINCDD.CSOP_GetNvmProtectState
            scp_CSOP_GetSWID: operation=R_HALINCDD.CSOP_GetSWID
            scp_CSOP_GetVinpAllowMoveThd: operation=R_HALINCDD.CSOP_GetVinpAllowMoveThdOta
            scp_CSOP_GetVinpPwrReqOta: operation=R_HALINCDD.CSOP_GetVinpPwrReqOta
            scp_CSOP_GetWISR: operation=R_HALINCDD.CSOP_GetWISR
            scp_CSOP_HALINCDD_DIRECT: operation=R_HALINCDD.CSOP_HALINCDD_DIRECT
            scp_CSOP_IVIReset: operation=R_HALOUTCDD.CSOP_IVIReset
            scp_CSOP_IMUGetOffsetVal: operation=R_HALIN_IMU.CSOP_IMUGetOffsetVal
            scp_CSOP_IMUGetSixAxisVal: operation=R_HALIN_IMU.CSOP_IMUGetSixAxisVal
            scp_CSOP_IMUSetSta: operation=R_HALIN_IMU.CSOP_IMUSetSta
            scp_CSOP_SetDTCStatus: operation=R_UDSCDD.CSOP_SetDTCStatus
            scp_CSOP_SetSysPwrStat: operation=R_HALOUTCDD.CSOP_SetSysPwrStat
            scp_CSOP_SleepRequest: operation=R_HALOUTCDD.CSOP_SleepRequest
            scp_CSOP_Write_CAN3_VCU1: operation=R_E2E_CAN3_VCU1.CSOP_Write_CAN3_VCU1
            scp_CSOP_Write_CAN3_VCU1_toNIDEC: operation=R_E2E_CAN3_VCU1_toNIDEC.CSOP_Write_CAN3_VCU1_toNIDEC
            scp_CSOP_Write_CAN4_VCU1: operation=R_E2E_CAN4_VCU1.CSOP_Write_CAN4_VCU1
            scp_NVM_ReadOperation: operation=R_NVMReadCDD_Inner.NVM_ReadOperation
            scp_NVM_WriteOperation: operation=R_NVMWriteCDD_Inner.NVM_WriteOperation
            scp_CSOP_DIDGet_XWDMode: operation=R_DIDReadCDD.CSOP_DIDGet_XWDMode
            scp_CSOP_DIDSet_XWDMode: operation=R_DIDWriteCDD.CSOP_DIDSet_XWDMode
            scp_CSOP_DIDGet_DKCKey: operation=R_DIDReadCDD.CSOP_DIDGet_DKCKey
            scp_CSOP_DIDSet_DKCKey: operation=R_DIDWriteCDD.CSOP_DIDSet_DKCKey
            scp_CSOP_DIDGet_DynoMode: operation=R_DIDReadCDD.CSOP_DIDGet_DynoMode
            scp_CSOP_DIDSet_DynoMode: operation=R_DIDWriteCDD.CSOP_DIDSet_DynoMode
            scp_CSOP_DIDSet_APPPedalZP: operation=R_DIDWriteCDD.CSOP_DIDSet_APPPedalZP
            scp_CSOP_DIDSet_NVMPedalZP: operation=R_DIDWriteCDD.CSOP_DIDSet_NVMPedalZP
            scp_CSOP_DIDGet_TurnLampFRThreCurr: operation=R_DIDReadCDD.CSOP_DIDGet_TurnLampFRThreCurr
            scp_CSOP_DIDSet_TurnLampFRThreCurr: operation=R_DIDWriteCDD.CSOP_DIDSet_TurnLampFRThreCurr
            scp_CSOP_DIDGet_TurnLampRRThreCurr: operation=R_DIDReadCDD.CSOP_DIDGet_TurnLampRRThreCurr
            scp_CSOP_DIDSet_TurnLampRRThreCurr: operation=R_DIDWriteCDD.CSOP_DIDSet_TurnLampRRThreCurr
            scp_CSOP_DIDGet_TurnLampFLThreCurr: operation=R_DIDReadCDD.CSOP_DIDGet_TurnLampFLThreCurr
            scp_CSOP_DIDSet_TurnLampFLThreCurr: operation=R_DIDWriteCDD.CSOP_DIDSet_TurnLampFLThreCurr
            scp_CSOP_DIDGet_TurnLampRLThreCurr: operation=R_DIDReadCDD.CSOP_DIDGet_TurnLampRLThreCurr
            scp_CSOP_DIDSet_TurnLampRLThreCurr: operation=R_DIDWriteCDD.CSOP_DIDSet_TurnLampRLThreCurr
            scp_CSOP_DIDGet_FMHTimer: operation=R_DIDReadCDD.CSOP_DIDGet_FMHTimer
            scp_CSOP_DIDSet_FMHTimer: operation=R_DIDWriteCDD.CSOP_DIDSet_FMHTimer
            scp_CSOP_DIDGet_AutoLock: operation=R_DIDReadCDD.CSOP_DIDGet_AutoLock
            scp_CSOP_DIDSet_AutoLock: operation=R_DIDWriteCDD.CSOP_DIDSet_AutoLock
            scp_CSOP_DIDGet_DRLDis: operation=R_DIDReadCDD.CSOP_DIDGet_DRLDis
            scp_CSOP_DIDSet_DRLDis: operation=R_DIDWriteCDD.CSOP_DIDSet_DRLDis
            scp_CSOP_DIDGet_AutoWipHSpdEN: operation=R_DIDReadCDD.CSOP_DIDGet_AutoWipHSpdEN
            scp_CSOP_DIDSet_AutoWipHSpdEN: operation=R_DIDWriteCDD.CSOP_DIDSet_AutoWipHSpdEN
            scp_CSOP_DIDGet_WipRLSCmdHoldFilter: operation=R_DIDReadCDD.CSOP_DIDGet_WipRLSCmdHoldFilter
            scp_CSOP_DIDSet_WipRLSCmdHoldFilter: operation=R_DIDWriteCDD.CSOP_DIDSet_WipRLSCmdHoldFilter
            scp_CSOP_DIDGet_WipRLSCmdCutFilter: operation=R_DIDReadCDD.CSOP_DIDGet_WipRLSCmdCutFilter
            scp_CSOP_DIDSet_WipRLSCmdCutFilter: operation=R_DIDWriteCDD.CSOP_DIDSet_WipRLSCmdCutFilter
            scp_CSOP_DIDSet_LFSensorID: operation=R_DIDWriteCDD.CSOP_DIDSet_LFSensorID
            scp_CSOP_DIDSet_RFSensorID: operation=R_DIDWriteCDD.CSOP_DIDSet_RFSensorID
            scp_CSOP_DIDSet_LRSensorID: operation=R_DIDWriteCDD.CSOP_DIDSet_LRSensorID
            scp_CSOP_DIDSet_RRSensorID: operation=R_DIDWriteCDD.CSOP_DIDSet_RRSensorID
            scp_CSOP_DIDSet_WhlPres: operation=R_DIDWriteCDD.CSOP_DIDSet_WhlPres
            scp_CSOP_DIDSet_WhlTmp: operation=R_DIDWriteCDD.CSOP_DIDSet_WhlTmp
            scp_CSOP_DIDSet_WhlSensorBattSta: operation=R_DIDWriteCDD.CSOP_DIDSet_WhlSensorBattSta
            scp_CSOP_DIDSet_LFLowPresThre: operation=R_DIDWriteCDD.CSOP_DIDSet_LFLowPresThre
            scp_CSOP_DIDSet_RFLowPresThre: operation=R_DIDWriteCDD.CSOP_DIDSet_RFLowPresThre
            scp_CSOP_DIDSet_LRLowPresThre: operation=R_DIDWriteCDD.CSOP_DIDSet_LRLowPresThre
            scp_CSOP_DIDSet_RRLowPresThre: operation=R_DIDWriteCDD.CSOP_DIDSet_RRLowPresThre
            scp_CSOP_DIDSet_SensorMode: operation=R_DIDWriteCDD.CSOP_DIDSet_SensorMode
            scp_CSOP_DIDSet_TPMSLearnSta: operation=R_DIDWriteCDD.CSOP_DIDSet_TPMSLearnSta
            scp_CSOP_DIDGet_USSConfig: operation=R_DIDReadCDD.CSOP_DIDGet_USSConfig
            scp_CSOP_DIDSet_USSConfig: operation=R_DIDWriteCDD.CSOP_DIDSet_USSConfig
            scp_CSOP_DIDGet_TireSize: operation=R_DIDReadCDD.CSOP_DIDGet_TireSize
            scp_CSOP_DIDSet_TireSize: operation=R_DIDWriteCDD.CSOP_DIDSet_TireSize
            scp_CSOP_DIDGet_APSFunConfig: operation=R_DIDReadCDD.CSOP_DIDGet_APSFunConfig
            scp_CSOP_DIDSet_APSFunConfig: operation=R_DIDWriteCDD.CSOP_DIDSet_APSFunConfig
            scp_CSOP_GetVinCode: operation=R_HALINCDD.CSOP_GetVinCode
          written-local-variables:
            29 x access:
              IRV_ms10_CAN1_SG_FD1_APS3: accessed-variable=IRV_ms10_CAN1_SG_FD1_APS3
              IRV_ms10_CAN1_SG_FD1_VCU2: accessed-variable=IRV_ms10_CAN1_SG_FD1_VCU2
              IRV_ms10_CAN1_SG_FD1_VCU3: accessed-variable=IRV_ms10_CAN1_SG_FD1_VCU3
              IRV_ms10_CAN1_SG_VMC_FCM1: accessed-variable=IRV_ms10_CAN1_SG_VMC_FCM1
              IRV_ms10_CAN3_SG_FD3_VCU0: accessed-variable=IRV_ms10_CAN3_SG_FD3_VCU0
              IRV_ms10_CAN3_SG_FD3_VCU2: accessed-variable=IRV_ms10_CAN3_SG_FD3_VCU2
              IRV_ms10_CAN3_SG_FD3_VCU2_toNIDEC: accessed-variable=IRV_ms10_CAN3_SG_FD3_VCU2_toNIDEC
              IRV_ms10_CAN3_SG_FD3_VCU5: accessed-variable=IRV_ms10_CAN3_SG_FD3_VCU5
              IRV_ms10_CAN3_SG_GW_ESC1_toNIDEC: accessed-variable=IRV_ms10_CAN3_SG_GW_ESC1_toNIDEC
              IRV_ms10_CAN5_SG_FD5_Debug3: accessed-variable=IRV_ms10_CAN5_SG_FD5_Debug3
              IRV_ms10_CAN6_SG_FD6_APS3: accessed-variable=IRV_ms10_CAN6_SG_FD6_APS3
              IRV_ms10_CAN6_SG_FD6_VCU2: accessed-variable=IRV_ms10_CAN6_SG_FD6_VCU2
              IRV_ms100_CAN1_SG_FD1_THCM1: accessed-variable=IRV_ms100_CAN1_SG_FD1_THCM1
              IRV_ms100_CAN3_SG_FD3_THCM1: accessed-variable=IRV_ms100_CAN3_SG_FD3_THCM1
              IRV_ms1000_CAN3_SG_GW_IVI6_toNIDEC: accessed-variable=IRV_ms1000_CAN3_SG_GW_IVI6_toNIDEC
              IRV_ms20_CAN1_SG_FD1_APS2: accessed-variable=IRV_ms20_CAN1_SG_FD1_APS2
              IRV_ms20_CAN2_SG_FD2_C20_0: accessed-variable=IRV_ms20_CAN2_SG_FD2_C20_0
              IRV_ms500_CAN1_SG_FD1_VMC2: accessed-variable=IRV_ms500_CAN1_SG_FD1_VMC2
              IRV_ms5000_CAN2_SG_FD2_Version: accessed-variable=IRV_ms5000_CAN2_SG_FD2_Version
              IRV_E2E_CAN3_SG_FD3_VCU1: accessed-variable=IRV_E2E_CAN3_SG_FD3_VCU1
              IRV_E2E_CAN3_SG_FD3_VCU1_toNIDEC: accessed-variable=IRV_E2E_CAN3_SG_FD3_VCU1_toNIDEC
              IRV_E2E_CAN4_SG_FD4_CE100_0: accessed-variable=IRV_E2E_CAN4_SG_FD4_CE100_0
              IRV_f32_ApsOutVehSpdSig: accessed-variable=IRV_f32_ApsOutVehSpdSig
              IRV_u8Array256_NvmWriteArray: accessed-variable=IRV_u8Array256_NvmWriteArray
              IRV_u8_ApsOutGearPosnSig: accessed-variable=IRV_u8_ApsOutGearPosnSig
              IRV_u8_ApsOutSendChrgPlugSta: accessed-variable=IRV_u8_ApsOutSendChrgPlugSta
              IRV_u8_ApsOutSetFrSensorOnCmd: accessed-variable=IRV_u8_ApsOutSetFrSensorOnCmd
              IRV_u8_ApsOutSetFrSensorSwTOCmd: accessed-variable=IRV_u8_ApsOutSetFrSensorSwTOCmd
              IRV_u8_ApsOutSetVehSpdTOCmd: accessed-variable=IRV_u8_ApsOutSetVehSpdTOCmd
        run_SWC_FDC_Tx_10ms
          data-send-points:
            12 x access:
              dsp_CAN1_SG_FD1_APS3: accessed-variable=P_CAN1_FD1_APS3.CAN1_SG_FD1_APS3
              dsp_CAN1_SG_FD1_VCU2: accessed-variable=P_CAN1_FD1_VCU2.CAN1_SG_FD1_VCU2
              dsp_CAN1_SG_FD1_VCU3: accessed-variable=P_CAN1_FD1_VCU3.CAN1_SG_FD1_VCU3
              dsp_CAN1_SG_VMC_FCM1: accessed-variable=P_CAN1_VMC_FCM1.CAN1_SG_VMC_FCM1
              dsp_CAN3_SG_FD3_VCU0: accessed-variable=P_CAN3_FD3_VCU0.CAN3_SG_FD3_VCU0
              dsp_CAN3_SG_FD3_VCU2: accessed-variable=P_CAN3_FD3_VCU2.CAN3_SG_FD3_VCU2
              dsp_CAN3_SG_FD3_VCU2_toNIDEC: accessed-variable=P_CAN3_FD3_VCU2_toNIDEC.CAN3_SG_FD3_VCU2_toNIDEC
              dsp_CAN3_SG_FD3_VCU5: accessed-variable=P_CAN3_FD3_VCU5.CAN3_SG_FD3_VCU5
              dsp_CAN3_SG_GW_ESC1_toNIDEC: accessed-variable=P_CAN3_GW_ESC1_toNIDEC.CAN3_SG_GW_ESC1_toNIDEC
              dsp_CAN5_SG_FD5_Debug3: accessed-variable=P_CAN5_FD5_Debug3.CAN5_SG_FD5_Debug3
              dsp_CAN6_SG_FD6_APS3: accessed-variable=P_CAN6_FD6_APS3.CAN6_SG_FD6_APS3
              dsp_CAN6_SG_FD6_VCU2: accessed-variable=P_CAN6_FD6_VCU2.CAN6_SG_FD6_VCU2
          read-local-variables:
            18 x access:
              IRV_ms10_CAN1_SG_FD1_APS3: accessed-variable=IRV_ms10_CAN1_SG_FD1_APS3
              IRV_ms10_CAN1_SG_FD1_VCU2: accessed-variable=IRV_ms10_CAN1_SG_FD1_VCU2
              IRV_ms10_CAN1_SG_FD1_VCU3: accessed-variable=IRV_ms10_CAN1_SG_FD1_VCU3
              IRV_ms10_CAN1_SG_VMC_FCM1: accessed-variable=IRV_ms10_CAN1_SG_VMC_FCM1
              IRV_ms10_CAN3_SG_FD3_VCU0: accessed-variable=IRV_ms10_CAN3_SG_FD3_VCU0
              IRV_ms10_CAN3_SG_FD3_VCU2: accessed-variable=IRV_ms10_CAN3_SG_FD3_VCU2
              IRV_ms10_CAN3_SG_FD3_VCU2_toNIDEC: accessed-variable=IRV_ms10_CAN3_SG_FD3_VCU2_toNIDEC
              IRV_ms10_CAN3_SG_FD3_VCU5: accessed-variable=IRV_ms10_CAN3_SG_FD3_VCU5
              IRV_ms10_CAN3_SG_GW_ESC1_toNIDEC: accessed-variable=IRV_ms10_CAN3_SG_GW_ESC1_toNIDEC
              IRV_ms10_CAN5_SG_FD5_Debug3: accessed-variable=IRV_ms10_CAN5_SG_FD5_Debug3
              IRV_ms10_CAN6_SG_FD6_APS3: accessed-variable=IRV_ms10_CAN6_SG_FD6_APS3
              IRV_ms10_CAN6_SG_FD6_VCU2: accessed-variable=IRV_ms10_CAN6_SG_FD6_VCU2
              IRV_f32_ApsOutVehSpdSig: accessed-variable=IRV_f32_ApsOutVehSpdSig
              IRV_u8_ApsOutGearPosnSig: accessed-variable=IRV_u8_ApsOutGearPosnSig
              IRV_u8_ApsOutSendChrgPlugSta: accessed-variable=IRV_u8_ApsOutSendChrgPlugSta
              IRV_u8_ApsOutSetFrSensorOnCmd: accessed-variable=IRV_u8_ApsOutSetFrSensorOnCmd
              IRV_u8_ApsOutSetFrSensorSwTOCmd: accessed-variable=IRV_u8_ApsOutSetFrSensorSwTOCmd
              IRV_u8_ApsOutSetVehSpdTOCmd: accessed-variable=IRV_u8_ApsOutSetVehSpdTOCmd
          6 x sync call, all with timeout=0.0:
            scp_CSOP_ApsGetDist: operation=R_HALIN_APS.CSOP_ApsGetDist
            scp_CSOP_ApsGetDistLevel: operation=R_HALIN_APS.CSOP_ApsGetDistLevel
            scp_CSOP_ApsGetUssSta: operation=R_HALIN_APS.CSOP_ApsGetUssSta
            scp_CSOP_ApsOutput: operation=R_HALOUT_APS.CSOP_ApsOutput
            scp_CSOP_GetAPSOtherStatus: operation=R_HALIN_APS.CSOP_ApsGetOtherStatus
            scp_CSOP_TPMS_GetRawData: operation=R_HALINCDD.CSOP_TPMS_GetRawData
          written-local-variables:
            10 x access:
              IRV_u16Array4_ApsInDist: accessed-variable=IRV_u16Array4_ApsInDist
              IRV_u8Array12_ApsInUssSta: accessed-variable=IRV_u8Array12_ApsInUssSta
              IRV_u8Array8_ApsInLevel: accessed-variable=IRV_u8Array8_ApsInLevel
              IRV_u8Array8_PasInDist: accessed-variable=IRV_u8Array8_PasInDist
              IRV_u8Array9_TPMSData: accessed-variable=IRV_u8Array9_TPMSData
              IRV_u8_ApsInPASChime: accessed-variable=IRV_u8_ApsInPASChime
              IRV_u8_ApsInSensorLayout: accessed-variable=IRV_u8_ApsInSensorLayout
              IRV_u8_ApsInSysFailSta: accessed-variable=IRV_u8_ApsInSysFailSta
              IRV_u8_ApsInSysMode: accessed-variable=IRV_u8_ApsInSysMode
              IRV_u8_TPMSDataInSta: accessed-variable=IRV_u8_TPMSDataInSta
        run_SWC_FDC_UDS_10ms
          sync call scp_CSOP_UDS_Main: operation=R_HALINCDD.CSOP_UDS_Main, timeout=0.0
